[part 1 of 2: packages /MICROSAR/Dem_swc/DataTypes to /MICROSAR/Dem_swc/ComponentTypes]
AUTOSAR XML (schema 4-0-3)
package /MICROSAR/Dem_swc/DataTypes
  21 x impl type:
    Dem_EventIdType: range raw 1..65535, implementation-data-type=uint16
    Dem_RatioIdType: range raw 1..65535, implementation-data-type=uint16
    Dem_DTCStatusMaskType: range raw 0..255, implementation-data-type=uint8
    Dem_OperationCycleIdType: range raw 0..255, implementation-data-type=uint8
    Dem_DTCGroupType: range raw 0..16777215, implementation-data-type=uint32
    Dem_EventStatusType: compu {0=DEM_EVENT_STATUS_PASSED, 1=DEM_EVENT_STATUS_FAILED, 2=DEM_EVENT_STATUS_PREPASSED, 3=DEM_EVENT_STATUS_PREFAILED}, implementation-data-type=uint8
    Dem_EventStatusExtendedType: compu {1=DEM_UDS_STATUS_TF, 2=DEM_UDS_STATUS_TFTOC, 4=DEM_UDS_STATUS_PDTC, 8=DEM_UDS_STATUS_CDTC, 16=DEM_UDS_STATUS_TNCSLC, 32=DEM_UDS_STATUS_TFSLC, 64=DEM_UDS_STATUS_TNCTOC, 128=DEM_UDS_STATUS_WIR}, implementation-data-type=uint8
    Dem_InitMonitorReasonType: compu {1=DEM_INIT_MONITOR_CLEAR, 2=DEM_INIT_MONITOR_RESTART, 3=DEM_INIT_MONITOR_REENABLED}, implementation-data-type=uint8
    Dem_DTCOriginType: compu {1=DEM_DTC_ORIGIN_PRIMARY_MEMORY, 2=DEM_DTC_ORIGIN_MIRROR_MEMORY, 3=DEM_DTC_ORIGIN_PERMANENT_MEMORY, 4=DEM_DTC_ORIGIN_SECONDARY_MEMORY}, implementation-data-type=uint8
    Dem_DTCFormatType: compu {0=DEM_DTC_FORMAT_OBD, 1=DEM_DTC_FORMAT_UDS, 2=DEM_DTC_FORMAT_J1939}, implementation-data-type=uint8
    Dem_OperationCycleStateType: compu {0=DEM_CYCLE_STATE_START, 1=DEM_CYCLE_STATE_END}, implementation-data-type=uint8
    Dem_IndicatorStatusType: compu {0=DEM_INDICATOR_OFF, 1=DEM_INDICATOR_CONTINUOUS, 2=DEM_INDICATOR_BLINKING, 3=DEM_INDICATOR_BLINK_CONT, 4=DEM_INDICATOR_SLOW_FLASH, 5=DEM_INDICATOR_FAST_FLASH, 6=DEM_INDICATOR_ON_DEMAND, 7=DEM_INDICATOR_SHORT}, implementation-data-type=uint8
    Dem_DTCKindType: compu {1=DEM_DTC_KIND_ALL_DTCS, 2=DEM_DTC_KIND_EMISSION_REL_DTCS}, implementation-data-type=uint8
    Dem_IumprDenomCondIdType: compu {1=DEM_IUMPR_GENERAL_DENOMINATOR, 2=DEM_IUMPR_DEN_COND_COLDSTART, 3=DEM_IUMPR_DEN_COND_EVAP, 4=DEM_IUMPR_DEN_COND_500MI}, implementation-data-type=uint8
    Dem_IumprDenomCondStatusType: compu {0=DEM_IUMPR_DEN_STATUS_NOT_REACHED, 1=DEM_IUMPR_DEN_STATUS_REACHED, 2=DEM_IUMPR_DEN_STATUS_INHIBITED}, implementation-data-type=uint8
    Dem_DebounceResetStatusType: compu {0=DEM_DEBOUNCE_STATUS_FREEZE, 1=DEM_DEBOUNCE_STATUS_RESET}, implementation-data-type=uint8
    Dem_DebouncingStateType: compu {1=DEM_TEMPORARILY_DEFECTIVE, 2=DEM_FINALLY_DEFECTIVE, 4=DEM_TEMPORARILY_HEALED, 8=DEM_TEST_COMPLETE, 16=DEM_DTR_UPDATE}, implementation-data-type=uint8
    DataArray_Type_2: category=ARRAY, sw-calibration-access=READ-ONLY
      element DataArray_Type_2Element: array-size=2, array-size-semantics=FIXED-SIZE, implementation-data-type=uint8
    DataArray_Type_1: category=ARRAY, sw-calibration-access=READ-ONLY
      element DataArray_Type_1Element: array-size=1, array-size-semantics=FIXED-SIZE, implementation-data-type=uint8
    DataArray_Type_4: category=ARRAY, sw-calibration-access=READ-ONLY
      element DataArray_Type_4Element: array-size=4, array-size-semantics=FIXED-SIZE, implementation-data-type=uint8
    Dem_MaxDataValueType: category=ARRAY, sw-calibration-access=READ-ONLY
      element Dem_MaxDataValueTypeElement: array-size=4, array-size-semantics=FIXED-SIZE, implementation-data-type=uint8
package /MICROSAR/Dem_swc/Interfaces
  30 x client server interface, all with is-service=true, service-kind=DIAGNOSTIC-EVENT-MANAGER:
    CddIf
      operation ClearDTC: possible-error=[CddIf/DEM_CLEAR_WRONG_DTC, CddIf/DEM_CLEAR_WRONG_DTCORIGIN, CddIf/DEM_CLEAR_FAILED, CddIf/DEM_CLEAR_PENDING, CddIf/DEM_CLEAR_BUSY]
        arg DTC: type=uint32, direction=IN
        arg DTCFormat: type=Dem_DTCFormatType, direction=IN
        arg DTCOrigin: type=Dem_DTCOriginType, direction=IN
      5 x error:
        DEM_CLEAR_WRONG_DTC: error-code=1
        DEM_CLEAR_WRONG_DTCORIGIN: error-code=2
        DEM_CLEAR_FAILED: error-code=3
        DEM_CLEAR_PENDING: error-code=4
        DEM_CLEAR_BUSY: error-code=5
    DemServices
      operation GetPostRunRequested: possible-error=DemServices/E_NOT_OK
        arg IsRequested: type=boolean, direction=OUT
      operation GetDTCStatusAvailabilityMask: possible-error=DemServices/E_NOT_OK
        arg DTCStatusMask: type=uint8, direction=OUT
      error E_NOT_OK: error-code=1
    EvMemOverflowIndication
      operation GetEventMemoryOverflow: possible-error=EvMemOverflowIndication/E_NOT_OK
        arg OverflowIndication: type=boolean, direction=OUT
      operation GetNumberOfEventMemoryEntries: possible-error=EvMemOverflowIndication/E_NOT_OK
        arg NumberOfEventMemoryEntries: type=uint8, direction=OUT
      error E_NOT_OK: error-code=1
    GeneralDiagnosticInfo
      9 x operation:
        GetEventStatus: possible-error=GeneralDiagnosticInfo/E_NOT_OK
          arg EventId: type=Dem_EventIdType, direction=IN
          arg EventStatusExtended: type=Dem_EventStatusExtendedType, direction=OUT
        GetEventFailed: possible-error=GeneralDiagnosticInfo/E_NOT_OK
          arg EventId: type=Dem_EventIdType, direction=IN
          arg EventFailed: type=boolean, direction=OUT
        GetEventTested: possible-error=GeneralDiagnosticInfo/E_NOT_OK
          arg EventId: type=Dem_EventIdType, direction=IN
          arg EventTested: type=boolean, direction=OUT
        GetDTCOfEvent: possible-error=[GeneralDiagnosticInfo/E_NOT_OK, GeneralDiagnosticInfo/DEM_E_NO_DTC_AVAILABLE]
          arg EventId: type=Dem_EventIdType, direction=IN
          arg DTCFormat: type=Dem_DTCFormatType, direction=IN
          arg DTCOfEvent: type=uint32, direction=OUT
        GetFaultDetectionCounter: possible-error=[GeneralDiagnosticInfo/E_NOT_OK, GeneralDiagnosticInfo/DEM_E_NO_FDC_AVAILABLE]
          arg EventId: type=Dem_EventIdType, direction=IN
          arg FaultDetectionCounter: type=sint8, direction=OUT
        GetEventFreezeFrameData: possible-error=[GeneralDiagnosticInfo/E_NOT_OK, GeneralDiagnosticInfo/DEM_E_NODATAAVAILABLE, GeneralDiagnosticInfo/DEM_E_WRONG_RECORDNUMBER, GeneralDiagnosticInfo/DEM_E_WRONG_DIDNUMBER]
          5 x arg:
            EventId: type=Dem_EventIdType, direction=IN
            RecordNumber: type=uint8, direction=IN
            ReportTotalRecord: type=boolean, direction=IN
            DataId: type=uint16, direction=IN
            DestBuffer: type=Dem_MaxDataValueType, direction=OUT
        GetEventExtendedDataRecord: possible-error=[GeneralDiagnosticInfo/E_NOT_OK, GeneralDiagnosticInfo/DEM_E_NODATAAVAILABLE, GeneralDiagnosticInfo/DEM_E_WRONG_RECORDNUMBER]
          arg EventId: type=Dem_EventIdType, direction=IN
          arg RecordNumber: type=uint8, direction=IN
          arg DestBuffer: type=Dem_MaxDataValueType, direction=OUT
        GetEventEnableCondition: possible-error=GeneralDiagnosticInfo/E_NOT_OK
          arg EventId: type=Dem_EventIdType, direction=IN
          arg ConditionFullfilled: type=boolean, direction=OUT
        GetDebouncingOfEvent: possible-error=GeneralDiagnosticInfo/E_NOT_OK
          arg EventId: type=Dem_EventIdType, direction=IN
          arg DebouncingState: type=Dem_DebouncingStateType, direction=OUT
      6 x error:
        E_NOT_OK: error-code=1
        DEM_E_NO_DTC_AVAILABLE: error-code=2
        DEM_E_NO_FDC_AVAILABLE: error-code=3
        DEM_E_NODATAAVAILABLE: error-code=48
        DEM_E_WRONG_RECORDNUMBER: error-code=49
        DEM_E_WRONG_DIDNUMBER: error-code=50
    DiagnosticInfo
      9 x operation:
        GetEventStatus: possible-error=DiagnosticInfo/E_NOT_OK
          arg EventStatusExtended: type=Dem_EventStatusExtendedType, direction=OUT
        GetEventFailed: possible-error=DiagnosticInfo/E_NOT_OK
          arg EventFailed: type=boolean, direction=OUT
        GetEventTested: possible-error=DiagnosticInfo/E_NOT_OK
          arg EventTested: type=boolean, direction=OUT
        GetDTCOfEvent: possible-error=[DiagnosticInfo/E_NOT_OK, DiagnosticInfo/DEM_E_NO_DTC_AVAILABLE]
          arg DTCFormat: type=Dem_DTCFormatType, direction=IN
          arg DTCOfEvent: type=uint32, direction=OUT
        GetFaultDetectionCounter: possible-error=[DiagnosticInfo/E_NOT_OK, DiagnosticInfo/DEM_E_NO_FDC_AVAILABLE]
          arg FaultDetectionCounter: type=sint8, direction=OUT
        GetEventFreezeFrameData: possible-error=[DiagnosticInfo/E_NOT_OK, DiagnosticInfo/DEM_E_NODATAAVAILABLE, DiagnosticInfo/DEM_E_WRONG_RECORDNUMBER, DiagnosticInfo/DEM_E_WRONG_DIDNUMBER]
          4 x arg:
            RecordNumber: type=uint8, direction=IN
            ReportTotalRecord: type=boolean, direction=IN
            DataId: type=uint16, direction=IN
            DestBuffer: type=Dem_MaxDataValueType, direction=OUT
        GetEventExtendedDataRecord: possible-error=[DiagnosticInfo/E_NOT_OK, DiagnosticInfo/DEM_E_NODATAAVAILABLE, DiagnosticInfo/DEM_E_WRONG_RECORDNUMBER]
          arg RecordNumber: type=uint8, direction=IN
          arg DestBuffer: type=Dem_MaxDataValueType, direction=OUT
        GetEventEnableCondition: possible-error=DiagnosticInfo/E_NOT_OK
          arg ConditionFullfilled: type=boolean, direction=OUT
        GetDebouncingOfEvent: possible-error=DiagnosticInfo/E_NOT_OK
          arg DebouncingState: type=Dem_DebouncingStateType, direction=OUT
      6 x error:
        E_NOT_OK: error-code=1
        DEM_E_NO_DTC_AVAILABLE: error-code=2
        DEM_E_NO_FDC_AVAILABLE: error-code=3
        DEM_E_NODATAAVAILABLE: error-code=48
        DEM_E_WRONG_RECORDNUMBER: error-code=49
        DEM_E_WRONG_DIDNUMBER: error-code=50
    DiagnosticMonitor
      10 x operation:
        SetEventStatus: possible-error=DiagnosticMonitor/E_NOT_OK
          arg EventStatus: type=Dem_EventStatusType, direction=IN
        ResetEventStatus: possible-error=DiagnosticMonitor/E_NOT_OK
        ResetEventDebounceStatus: possible-error=DiagnosticMonitor/E_NOT_OK
          arg DebounceResetStatus: type=Dem_DebounceResetStatusType, direction=IN
        GetEventStatus: possible-error=DiagnosticMonitor/E_NOT_OK
          arg EventStatusExtended: type=Dem_EventStatusExtendedType, direction=OUT
        GetEventFailed: possible-error=DiagnosticMonitor/E_NOT_OK
          arg EventFailed: type=boolean, direction=OUT
        GetEventTested: possible-error=DiagnosticMonitor/E_NOT_OK
          arg EventTested: type=boolean, direction=OUT
        GetDTCOfEvent: possible-error=[DiagnosticMonitor/E_NOT_OK, DiagnosticMonitor/DEM_E_NO_DTC_AVAILABLE]
          arg DTCFormat: type=Dem_DTCFormatType, direction=IN
          arg DTCOfEvent: type=uint32, direction=OUT
        GetFaultDetectionCounter: possible-error=[DiagnosticMonitor/E_NOT_OK, DiagnosticMonitor/DEM_E_NO_FDC_AVAILABLE]
          arg FaultDetectionCounter: type=sint8, direction=OUT
        GetEventFreezeFrameData: possible-error=[DiagnosticMonitor/E_NOT_OK, DiagnosticMonitor/DEM_E_NODATAAVAILABLE, DiagnosticMonitor/DEM_E_WRONG_RECORDNUMBER, DiagnosticMonitor/DEM_E_WRONG_DIDNUMBER]
          4 x arg:
            RecordNumber: type=uint8, direction=IN
            ReportTotalRecord: type=boolean, direction=IN
            DataId: type=uint16, direction=IN
            DestBuffer: type=Dem_MaxDataValueType, direction=OUT
        GetEventExtendedDataRecord: possible-error=[DiagnosticMonitor/E_NOT_OK, DiagnosticMonitor/DEM_E_NODATAAVAILABLE, DiagnosticMonitor/DEM_E_WRONG_RECORDNUMBER]
          arg RecordNumber: type=uint8, direction=IN
          arg DestBuffer: type=Dem_MaxDataValueType, direction=OUT
      6 x error:
        E_NOT_OK: error-code=1
        DEM_E_NO_DTC_AVAILABLE: error-code=2
        DEM_E_NO_FDC_AVAILABLE: error-code=3
        DEM_E_NODATAAVAILABLE: error-code=48
        DEM_E_WRONG_RECORDNUMBER: error-code=49
        DEM_E_WRONG_DIDNUMBER: error-code=50
    EnableCondition
      operation SetEnableCondition: possible-error=EnableCondition/E_NOT_OK
        arg ConditionFulfilled: type=boolean, direction=IN
      error E_NOT_OK: error-code=1
    CSDataServices_IgnCycCntr
      operation ReadData: possible-error=CSDataServices_IgnCycCntr/E_NOT_OK
        arg Data: type=DataArray_Type_2, direction=OUT
      error E_NOT_OK: error-code=1
    CSDataServices_EcuIntT
      operation ReadData: possible-error=CSDataServices_EcuIntT/E_NOT_OK
        arg Data: type=DataArray_Type_1, direction=OUT
      error E_NOT_OK: error-code=1
    IndicatorStatus
      operation GetIndicatorStatus: possible-error=IndicatorStatus/E_NOT_OK
        arg IndicatorStatus: type=Dem_IndicatorStatusType, direction=OUT
      error E_NOT_OK: error-code=1
    CSDataServices_SteerWhlAg
      operation ReadData: possible-error=CSDataServices_SteerWhlAg/E_NOT_OK
        arg Data: type=DataArray_Type_2, direction=OUT
      error E_NOT_OK: error-code=1
    CSDataServices_SteerInpTq
      operation ReadData: possible-error=CSDataServices_SteerInpTq/E_NOT_OK
        arg Data: type=DataArray_Type_2, direction=OUT
      error E_NOT_OK: error-code=1
    CSDataServices_EpdMotOvldProtnCntr
      operation ReadData: possible-error=CSDataServices_EpdMotOvldProtnCntr/E_NOT_OK
        arg Data: type=DataArray_Type_1, direction=OUT
      error E_NOT_OK: error-code=1
    CSDataServices_EngSpd
      operation ReadData: possible-error=CSDataServices_EngSpd/E_NOT_OK
        arg Data: type=DataArray_Type_2, direction=OUT
      error E_NOT_OK: error-code=1
    CSDataServices_VehSpd
      operation ReadData: possible-error=CSDataServices_VehSpd/E_NOT_OK
        arg Data: type=DataArray_Type_1, direction=OUT
      error E_NOT_OK: error-code=1
    CSDataServices_EpsMotCurr
      operation ReadData: possible-error=CSDataServices_EpsMotCurr/E_NOT_OK
        arg Data: type=DataArray_Type_2, direction=OUT
      error E_NOT_OK: error-code=1
    CSDataServices_EpsMotCurrFb
      operation ReadData: possible-error=CSDataServices_EpsMotCurrFb/E_NOT_OK
        arg Data: type=DataArray_Type_2, direction=OUT
      error E_NOT_OK: error-code=1
    CSDataServices_EpsTqOvrlSts
      operation ReadData: possible-error=CSDataServices_EpsTqOvrlSts/E_NOT_OK
        arg Data: type=DataArray_Type_1, direction=OUT
      error E_NOT_OK: error-code=1
    CSDataServices_EpsAgOvrlSts
      operation ReadData: possible-error=CSDataServices_EpsAgOvrlSts/E_NOT_OK
        arg Data: type=DataArray_Type_1, direction=OUT
      error E_NOT_OK: error-code=1
    CSDataServices_EpsTqOvrlReq
      operation ReadData: possible-error=CSDataServices_EpsTqOvrlReq/E_NOT_OK
        arg Data: type=DataArray_Type_2, direction=OUT
      error E_NOT_OK: error-code=1
    CSDataServices_SteerOutpTq
      operation ReadData: possible-error=CSDataServices_SteerOutpTq/E_NOT_OK
        arg Data: type=DataArray_Type_2, direction=OUT
      error E_NOT_OK: error-code=1
    CSDataServices_EpsStopStrtSts
      operation ReadData: possible-error=CSDataServices_EpsStopStrtSts/E_NOT_OK
        arg Data: type=DataArray_Type_1, direction=OUT
      error E_NOT_OK: error-code=1
    CSDataServices_EpsApaAgOvrlReq
      operation ReadData: possible-error=CSDataServices_EpsApaAgOvrlReq/E_NOT_OK
        arg Data: type=DataArray_Type_2, direction=OUT
      error E_NOT_OK: error-code=1
    CSDataServices_SysPwrMod
      operation ReadData: possible-error=CSDataServices_SysPwrMod/E_NOT_OK
        arg Data: type=DataArray_Type_1, direction=OUT
      error E_NOT_OK: error-code=1
    CSDataServices_BattVltgEcu
      operation ReadData: possible-error=CSDataServices_BattVltgEcu/E_NOT_OK
        arg Data: type=DataArray_Type_1, direction=OUT
      error E_NOT_OK: error-code=1
    CSDataServices_SplrIntDtcInfo
      operation ReadData: possible-error=CSDataServices_SplrIntDtcInfo/E_NOT_OK
        arg Data: type=DataArray_Type_4, direction=OUT
      error E_NOT_OK: error-code=1
    CSDataServices_TiIgnOn
      operation ReadData: possible-error=CSDataServices_TiIgnOn/E_NOT_OK
        arg Data: type=DataArray_Type_4, direction=OUT
      error E_NOT_OK: error-code=1
    DcmIf
      5 x operation:
        DcmClearDTC: possible-error=[DcmIf/DEM_CLEAR_WRONG_DTC, DcmIf/DEM_CLEAR_WRONG_DTCORIGIN, DcmIf/DEM_CLEAR_FAILED, DcmIf/DEM_CLEAR_PENDING, DcmIf/DEM_CLEAR_BUSY]
          arg DTC: type=uint32, direction=IN
          arg DTCFormat: type=Dem_DTCFormatType, direction=IN
          arg DTCOrigin: type=Dem_DTCOriginType, direction=IN
        DcmGetNextFilteredDTCAndFDC: possible-error=DEM_FILTERED_NO_MATCHING_DTC
          arg DTC: type=uint32, direction=OUT
          arg DTCFaultDetectionCounter: type=sint8, direction=OUT
        DcmEnableDTCSetting: possible-error=[DEM_CONTROL_DTC_SETTING_N_OK, DEM_CONTROL_DTC_WRONG_DTCGROUP]
          arg DTCGroup: type=Dem_DTCGroupType, direction=IN
          arg DTCKind: type=Dem_DTCKindType, direction=IN
        DcmGetFreezeFrameDataByDTC: possible-error=[DEM_GET_FFDATABYDTC_WRONG_DTC, DEM_GET_FFDATABYDTC_WRONG_DTCORIGIN, DEM_GET_FFDATABYDTC_WRONG_RECORDNUMBER, DEM_GET_FFDATABYDTC_WRONG_BUFFERSIZE, DEM_GET_FFDATABYDTC_PENDING]
          5 x arg:
            DTC: type=uint32, direction=IN
            DTCOrigin: type=Dem_DTCOriginType, direction=IN
            RecordNumber: type=uint8, direction=IN
            DestBuffer: type=uint8, direction=OUT
            BufSize: type=uint16, direction=INOUT
        DcmGetExtendedDataRecordByDTC: possible-error=[DEM_RECORD_WRONG_DTC, DEM_RECORD_WRONG_DTCORIGIN, DEM_RECORD_WRONG_NUMBER, DEM_RECORD_WRONG_BUFFERSIZE, DEM_RECORD_PENDING]
          5 x arg:
            DTC: type=uint32, direction=IN
            DTCOrigin: type=Dem_DTCOriginType, direction=IN
            ExtendedDataNumber: type=uint8, direction=IN
            DestBuffer: type=uint8, direction=OUT
            BufSize: type=uint16, direction=INOUT
      18 x error:
        DEM_CLEAR_WRONG_DTC: error-code=1
        DEM_CONTROL_DTC_SETTING_N_OK: error-code=1
        DEM_FILTERED_NO_MATCHING_DTC: error-code=1
        DEM_GET_FFDATABYDTC_WRONG_DTC: error-code=1
        DEM_RECORD_WRONG_DTC: error-code=1
        DEM_CLEAR_WRONG_DTCORIGIN: error-code=2
        DEM_CONTROL_DTC_WRONG_DTCGROUP: error-code=2
        DEM_GET_FFDATABYDTC_WRONG_DTCORIGIN: error-code=2
        DEM_RECORD_WRONG_DTCORIGIN: error-code=2
        DEM_CLEAR_FAILED: error-code=3
        DEM_GET_FFDATABYDTC_WRONG_RECORDNUMBER: error-code=3
        DEM_RECORD_WRONG_NUMBER: error-code=3
        DEM_CLEAR_PENDING: error-code=4
        DEM_GET_FFDATABYDTC_WRONG_BUFFERSIZE: error-code=4
        DEM_RECORD_WRONG_BUFFERSIZE: error-code=4
        DEM_CLEAR_BUSY: error-code=5
        DEM_GET_FFDATABYDTC_PENDING: error-code=5
        DEM_RECORD_PENDING: error-code=5
    OperationCycle
      operation SetOperationCycleState: possible-error=OperationCycle/E_NOT_OK
        arg CycleState: type=Dem_OperationCycleStateType, direction=IN
      error E_NOT_OK: error-code=1
    CallbackDTCStatusChange
      operation DTCStatusChanged: possible-error=CallbackDTCStatusChange/E_NOT_OK
        arg DTC: type=uint32, direction=IN
        arg DTCStatusOld: type=Dem_DTCStatusMaskType, direction=IN
        arg DTCStatusNew: type=Dem_DTCStatusMaskType, direction=IN
      error E_NOT_OK: error-code=1
package /MICROSAR/Dem_swc/ComponentTypes
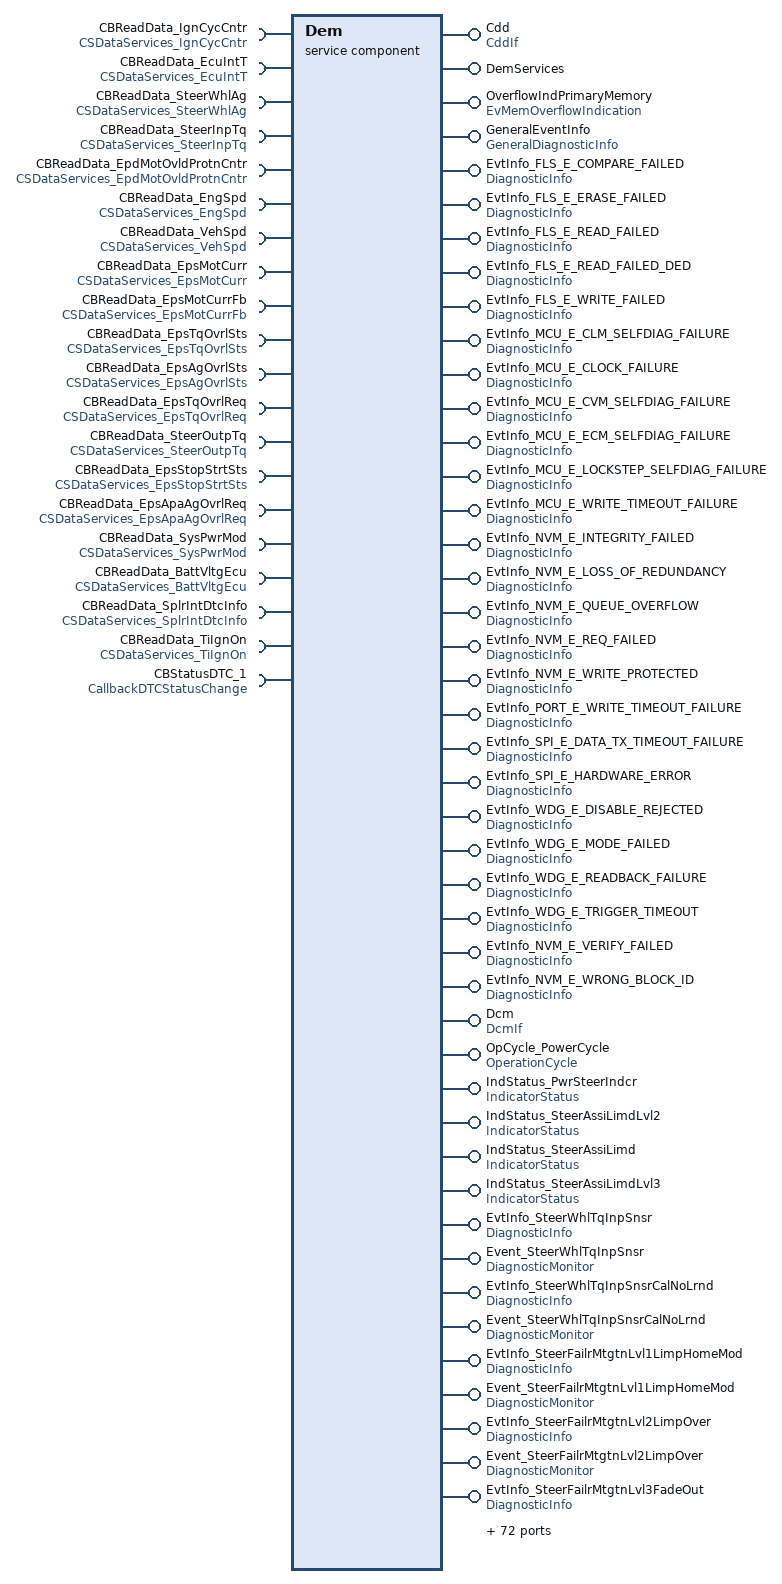
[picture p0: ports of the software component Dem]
  service sw component type Dem: category=SERVICE_COMPONENT
    29 x provide port:
      Cdd: provided-interface=CddIf
      DemServices: provided-interface=DemServices
      OverflowIndPrimaryMemory: provided-interface=EvMemOverflowIndication
      GeneralEventInfo: provided-interface=GeneralDiagnosticInfo
      EvtInfo_FLS_E_COMPARE_FAILED: provided-interface=DiagnosticInfo
      EvtInfo_FLS_E_ERASE_FAILED: provided-interface=DiagnosticInfo
      EvtInfo_FLS_E_READ_FAILED: provided-interface=DiagnosticInfo
      EvtInfo_FLS_E_READ_FAILED_DED: provided-interface=DiagnosticInfo
      EvtInfo_FLS_E_WRITE_FAILED: provided-interface=DiagnosticInfo
      EvtInfo_MCU_E_CLM_SELFDIAG_FAILURE: provided-interface=DiagnosticInfo
      EvtInfo_MCU_E_CLOCK_FAILURE: provided-interface=DiagnosticInfo
      EvtInfo_MCU_E_CVM_SELFDIAG_FAILURE: provided-interface=DiagnosticInfo
      EvtInfo_MCU_E_ECM_SELFDIAG_FAILURE: provided-interface=DiagnosticInfo
      EvtInfo_MCU_E_LOCKSTEP_SELFDIAG_FAILURE: provided-interface=DiagnosticInfo
      EvtInfo_MCU_E_WRITE_TIMEOUT_FAILURE: provided-interface=DiagnosticInfo
      EvtInfo_NVM_E_INTEGRITY_FAILED: provided-interface=DiagnosticInfo
      EvtInfo_NVM_E_LOSS_OF_REDUNDANCY: provided-interface=DiagnosticInfo
      EvtInfo_NVM_E_QUEUE_OVERFLOW: provided-interface=DiagnosticInfo
      EvtInfo_NVM_E_REQ_FAILED: provided-interface=DiagnosticInfo
      EvtInfo_NVM_E_WRITE_PROTECTED: provided-interface=DiagnosticInfo
      EvtInfo_PORT_E_WRITE_TIMEOUT_FAILURE: provided-interface=DiagnosticInfo
      EvtInfo_SPI_E_DATA_TX_TIMEOUT_FAILURE: provided-interface=DiagnosticInfo
      EvtInfo_SPI_E_HARDWARE_ERROR: provided-interface=DiagnosticInfo
      EvtInfo_WDG_E_DISABLE_REJECTED: provided-interface=DiagnosticInfo
      EvtInfo_WDG_E_MODE_FAILED: provided-interface=DiagnosticInfo
      EvtInfo_WDG_E_READBACK_FAILURE: provided-interface=DiagnosticInfo
      EvtInfo_WDG_E_TRIGGER_TIMEOUT: provided-interface=DiagnosticInfo
      EvtInfo_NVM_E_VERIFY_FAILED: provided-interface=DiagnosticInfo
      EvtInfo_NVM_E_WRONG_BLOCK_ID: provided-interface=DiagnosticInfo
    19 x require port:
      CBReadData_IgnCycCntr: required-interface=CSDataServices_IgnCycCntr
      CBReadData_EcuIntT: required-interface=CSDataServices_EcuIntT
      CBReadData_SteerWhlAg: required-interface=CSDataServices_SteerWhlAg
      CBReadData_SteerInpTq: required-interface=CSDataServices_SteerInpTq
      CBReadData_EpdMotOvldProtnCntr: required-interface=CSDataServices_EpdMotOvldProtnCntr
      CBReadData_EngSpd: required-interface=CSDataServices_EngSpd
      CBReadData_VehSpd: required-interface=CSDataServices_VehSpd
      CBReadData_EpsMotCurr: required-interface=CSDataServices_EpsMotCurr
      CBReadData_EpsMotCurrFb: required-interface=CSDataServices_EpsMotCurrFb
      CBReadData_EpsTqOvrlSts: required-interface=CSDataServices_EpsTqOvrlSts
      CBReadData_EpsAgOvrlSts: required-interface=CSDataServices_EpsAgOvrlSts
      CBReadData_EpsTqOvrlReq: required-interface=CSDataServices_EpsTqOvrlReq
      CBReadData_SteerOutpTq: required-interface=CSDataServices_SteerOutpTq
      CBReadData_EpsStopStrtSts: required-interface=CSDataServices_EpsStopStrtSts
      CBReadData_EpsApaAgOvrlReq: required-interface=CSDataServices_EpsApaAgOvrlReq
      CBReadData_SysPwrMod: required-interface=CSDataServices_SysPwrMod
      CBReadData_BattVltgEcu: required-interface=CSDataServices_BattVltgEcu
      CBReadData_SplrIntDtcInfo: required-interface=CSDataServices_SplrIntDtcInfo
      CBReadData_TiIgnOn: required-interface=CSDataServices_TiIgnOn
    32 x provide port:
      Dcm: provided-interface=DcmIf
      OpCycle_PowerCycle: provided-interface=OperationCycle
      IndStatus_PwrSteerIndcr: provided-interface=IndicatorStatus
      IndStatus_SteerAssiLimdLvl2: provided-interface=IndicatorStatus
      IndStatus_SteerAssiLimd: provided-interface=IndicatorStatus
      IndStatus_SteerAssiLimdLvl3: provided-interface=IndicatorStatus
      EvtInfo_SteerWhlTqInpSnsr: provided-interface=DiagnosticInfo
      Event_SteerWhlTqInpSnsr: provided-interface=DiagnosticMonitor
      EvtInfo_SteerWhlTqInpSnsrCalNoLrnd: provided-interface=DiagnosticInfo
      Event_SteerWhlTqInpSnsrCalNoLrnd: provided-interface=DiagnosticMonitor
      EvtInfo_SteerFailrMtgtnLvl1LimpHomeMod: provided-interface=DiagnosticInfo
      Event_SteerFailrMtgtnLvl1LimpHomeMod: provided-interface=DiagnosticMonitor
      EvtInfo_SteerFailrMtgtnLvl2LimpOver: provided-interface=DiagnosticInfo
      Event_SteerFailrMtgtnLvl2LimpOver: provided-interface=DiagnosticMonitor
      EvtInfo_SteerFailrMtgtnLvl3FadeOut: provided-interface=DiagnosticInfo
      Event_SteerFailrMtgtnLvl3FadeOut: provided-interface=DiagnosticMonitor
      EvtInfo_LostComWithEngCtrlMod: provided-interface=DiagnosticInfo
      Event_LostComWithEngCtrlMod: provided-interface=DiagnosticMonitor
      EvtInfo_LostComWithTrsmCtrlMod: provided-interface=DiagnosticInfo
      Event_LostComWithTrsmCtrlMod: provided-interface=DiagnosticMonitor
      EvtInfo_LostComWithElecBrkCtrlMod: provided-interface=DiagnosticInfo
      Event_LostComWithElecBrkCtrlMod: provided-interface=DiagnosticMonitor
      EvtInfo_LostComWithBodyCtrlMod: provided-interface=DiagnosticInfo
      Event_LostComWithBodyCtrlMod: provided-interface=DiagnosticMonitor
      EvtInfo_LostComWithParkAssiCtrlMod: provided-interface=DiagnosticInfo
      Event_LostComWithParkAssiCtrlMod: provided-interface=DiagnosticMonitor
      EvtInfo_LostComWithFrntCameraCtrlMod: provided-interface=DiagnosticInfo
      Event_LostComWithFrntCameraCtrlMod: provided-interface=DiagnosticMonitor
      EvtInfo_InvldDataRxdFromTrsmCtrlMod: provided-interface=DiagnosticInfo
      Event_InvldDataRxdFromTrsmCtrlMod: provided-interface=DiagnosticMonitor
      EvtInfo_LostComWithElecBrkCtrlModChassisExp: provided-interface=DiagnosticInfo
      Event_LostComWithElecBrkCtrlModChassisExp: provided-interface=DiagnosticMonitor
    require port CBStatusDTC_1: required-interface=CallbackDTCStatusChange
    55 x provide port:
      EvtInfo_CtrlrComChassisExpBusOff: provided-interface=DiagnosticInfo
      Event_CtrlrComChassisExpBusOff: provided-interface=DiagnosticMonitor
      EvtInfo_CtrlrComHiSpdBusOff: provided-interface=DiagnosticInfo
      Event_CtrlrComHiSpdBusOff: provided-interface=DiagnosticMonitor
      EvtInfo_DevPwrVltgOverMaxThd: provided-interface=DiagnosticInfo
      Event_DevPwrVltgOverMaxThd: provided-interface=DiagnosticMonitor
      EvtInfo_DevPwrVltgUnderMinThd: provided-interface=DiagnosticInfo
      Event_DevPwrVltgUnderMinThd: provided-interface=DiagnosticMonitor
      EvtInfo_EcuHwPrfmc: provided-interface=DiagnosticInfo
      Event_EcuHwPrfmc: provided-interface=DiagnosticMonitor
      EvtInfo_DevPwrVltgUnderThd: provided-interface=DiagnosticInfo
      Event_DevPwrVltgUnderThd: provided-interface=DiagnosticMonitor
      EvtInfo_ElecSteerMotCirc: provided-interface=DiagnosticInfo
      Event_ElecSteerMotCirc: provided-interface=DiagnosticMonitor
      EvtInfo_EcuSwPrfmcCalDataSetNotProgd: provided-interface=DiagnosticInfo
      Event_EcuSwPrfmcCalDataSetNotProgd: provided-interface=DiagnosticMonitor
      EvtInfo_ElecSteerMotPosSnsrCir: provided-interface=DiagnosticInfo
      Event_ElecSteerMotPosSnsrCir: provided-interface=DiagnosticMonitor
      EvtInfo_InvldDataRxdFromBodtCtrlMod: provided-interface=DiagnosticInfo
      Event_InvldDataRxdFromBodtCtrlMod: provided-interface=DiagnosticMonitor
      EvtInfo_InvldDataRxdFromElecBrkCtrlModChassisExp: provided-interface=DiagnosticInfo
      Event_InvldDataRxdFromElecBrkCtrlModChassisExp: provided-interface=DiagnosticMonitor
      EvtInfo_InvldDataRxdFromElecBrkCtrlMod: provided-interface=DiagnosticInfo
      Event_InvldDataRxdFromElecBrkCtrlMod: provided-interface=DiagnosticMonitor
      EvtInfo_SteerWheelAgSnsrCalNorPrfmd: provided-interface=DiagnosticInfo
      Event_SteerWheelAgSnsrCalNorPrfmd: provided-interface=DiagnosticMonitor
      EvtInfo_InvldDataRxdFromEngCtrlMod: provided-interface=DiagnosticInfo
      Event_InvldDataRxdFromEngCtrlMod: provided-interface=DiagnosticMonitor
      EvtInfo_InvldDataRxdFromFrntCameraMod: provided-interface=DiagnosticInfo
      Event_InvldDataRxdFromFrntCameraMod: provided-interface=DiagnosticMonitor
      EvtInfo_InvldDataRxdFromParkAssiCtrlMod: provided-interface=DiagnosticInfo
      Event_InvldDataRxdFromParkAssiCtrlMod: provided-interface=DiagnosticMonitor
      EvtInfo_SteerWheelAgSnsrHwFlt: provided-interface=DiagnosticInfo
      Event_SteerWheelAgSnsrHwFlt: provided-interface=DiagnosticMonitor
      EvtInfo_SteerWheelAgSnsrPlausly: provided-interface=DiagnosticInfo
      Event_SteerWheelAgSnsrPlausly: provided-interface=DiagnosticMonitor
      EvtInfo_SysThermErrTHi: provided-interface=DiagnosticInfo
      Event_SysThermErrTHi: provided-interface=DiagnosticMonitor
      EnableCond_DemEnableConditionJ: provided-interface=EnableCondition
      EnableCond_DemEnableConditionA: provided-interface=EnableCondition
      EnableCond_DemEnableConditionB: provided-interface=EnableCondition
      EnableCond_DemEnableConditionC: provided-interface=EnableCondition
      EnableCond_DemEnableConditionD: provided-interface=EnableCondition
      EnableCond_DemEnableConditionE: provided-interface=EnableCondition
      EnableCond_DemEnableConditionF: provided-interface=EnableCondition
      EnableCond_DemEnableConditionG: provided-interface=EnableCondition
      EnableCond_DemEnableConditionH: provided-interface=EnableCondition
      EnableCond_DemEnableConditionI: provided-interface=EnableCondition
      EnableCond_DemEnableConditionK: provided-interface=EnableCondition
      EvtInfo_DIO_E_REG_WRITE_VERIFY: provided-interface=DiagnosticInfo
      EvtInfo_MCU_E_INT_INCONSISTENT: provided-interface=DiagnosticInfo
      EvtInfo_MCU_E_REG_WRITE_VERIFY: provided-interface=DiagnosticInfo
      EvtInfo_PORT_E_REG_WRITE_VERIFY: provided-interface=DiagnosticInfo
      EvtInfo_WDG_59_DRIVERA_E_INT_INCONSISTENT: provided-interface=DiagnosticInfo
      EvtInfo_Wdg_E_REG_WRITE_VERIFY: provided-interface=DiagnosticInfo
